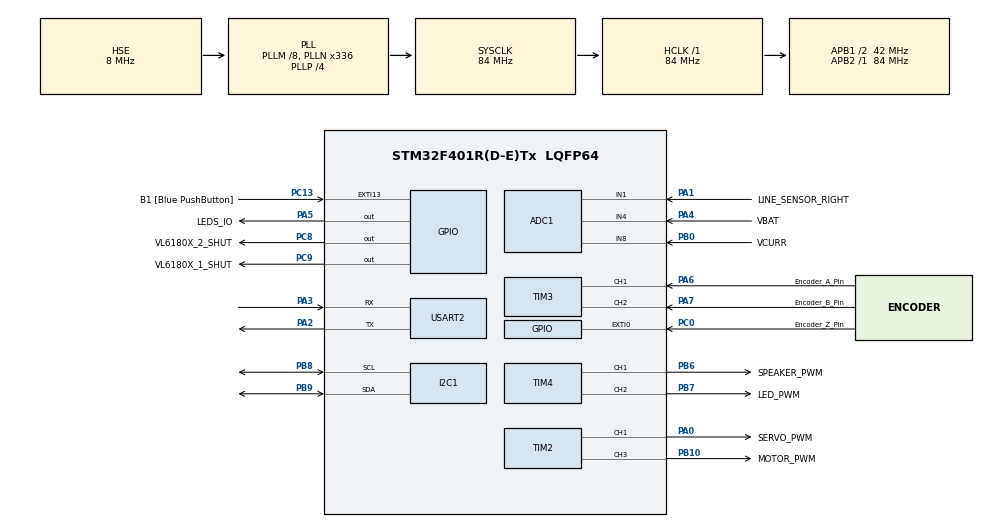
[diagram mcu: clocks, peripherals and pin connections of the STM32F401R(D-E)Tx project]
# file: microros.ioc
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ADC1.Channel-1\#ChannelRegularConversion=ADC_CHANNEL_1
ADC1.Channel-2\#ChannelRegularConversion=ADC_CHANNEL_4
ADC1.Channel-3\#ChannelRegularConversion=ADC_CHANNEL_8
ADC1.ContinuousConvMode=ENABLE
ADC1.DMAContinuousRequests=ENABLE
ADC1.EOCSelection=ADC_EOC_SEQ_CONV
ADC1.NbrOfConversion=3
ADC1.NbrOfConversionFlag=1
ADC1.Rank-1\#ChannelRegularConversion=1
ADC1.Rank-2\#ChannelRegularConversion=2
ADC1.Rank-3\#ChannelRegularConversion=3
ADC1.SamplingTime-1\#ChannelRegularConversion=ADC_SAMPLETIME_480CYCLES
ADC1.SamplingTime-2\#ChannelRegularConversion=ADC_SAMPLETIME_480CYCLES
ADC1.SamplingTime-3\#ChannelRegularConversion=ADC_SAMPLETIME_480CYCLES
ADC1.ScanConvMode=ENABLE
ADC1.master=1
Dma.ADC1.2.Direction=DMA_PERIPH_TO_MEMORY
Dma.ADC1.2.FIFOMode=DMA_FIFOMODE_DISABLE
Dma.ADC1.2.Instance=DMA2_Stream0
Dma.ADC1.2.MemDataAlignment=DMA_MDATAALIGN_WORD
Dma.ADC1.2.MemInc=DMA_MINC_ENABLE
Dma.ADC1.2.Mode=DMA_CIRCULAR
Dma.ADC1.2.PeriphDataAlignment=DMA_PDATAALIGN_WORD
Dma.ADC1.2.PeriphInc=DMA_PINC_DISABLE
Dma.ADC1.2.Priority=DMA_PRIORITY_MEDIUM
Dma.Request0=USART2_RX
Dma.Request1=USART2_TX
Dma.Request2=ADC1
Dma.USART2_RX.0.Direction=DMA_PERIPH_TO_MEMORY
Dma.USART2_RX.0.FIFOMode=DMA_FIFOMODE_DISABLE
Dma.USART2_RX.0.Instance=DMA1_Stream5
Dma.USART2_RX.0.MemDataAlignment=DMA_MDATAALIGN_BYTE
Dma.USART2_RX.0.MemInc=DMA_MINC_ENABLE
Dma.USART2_RX.0.Mode=DMA_CIRCULAR
Dma.USART2_RX.0.PeriphDataAlignment=DMA_PDATAALIGN_BYTE
Dma.USART2_RX.0.PeriphInc=DMA_PINC_DISABLE
Dma.USART2_RX.0.Priority=DMA_PRIORITY_VERY_HIGH
Dma.USART2_TX.1.Direction=DMA_MEMORY_TO_PERIPH
Dma.USART2_TX.1.FIFOMode=DMA_FIFOMODE_DISABLE
Dma.USART2_TX.1.Instance=DMA1_Stream6
Dma.USART2_TX.1.MemDataAlignment=DMA_MDATAALIGN_BYTE
Dma.USART2_TX.1.MemInc=DMA_MINC_ENABLE
Dma.USART2_TX.1.Mode=DMA_NORMAL
Dma.USART2_TX.1.PeriphDataAlignment=DMA_PDATAALIGN_BYTE
Dma.USART2_TX.1.PeriphInc=DMA_PINC_DISABLE
Dma.USART2_TX.1.Priority=DMA_PRIORITY_VERY_HIGH
FREERTOS.Tasks01=defaultTask,24,3000,StartDefaultTask,Default,NULL,Static,defaultTaskBuffer,defaultTaskControlBlock
Mcu.Family=STM32F4
Mcu.Name=STM32F401R(D-E)Tx
Mcu.Package=LQFP64
Mcu.UserConstants=PUB_COUNT_MAX,14999;SERVO_PWM_COUNT_MAX,39999;SERVO_PRESCALER,41;ENC_COUNT_MAX,999;MOT_PRESCALER,41;ENC_PRESCALER,83;RASPI_UART_BAUD,1000000;PUB_PRESCALER,83;MOT_PWM_COUNT_MAX,39999
NVIC.DMA1_Stream5_IRQn=true\:5\:0\:false\:false\:true\:true\:false\:true\:true
NVIC.DMA1_Stream6_IRQn=true\:5\:0\:false\:false\:true\:true\:false\:true\:true
NVIC.DMA2_Stream0_IRQn=true\:5\:0\:false\:false\:true\:true\:false\:true\:true
NVIC.EXTI0_IRQn=true\:5\:0\:false\:false\:true\:true\:true\:true\:true
NVIC.EXTI15_10_IRQn=true\:5\:0\:false\:false\:true\:true\:true\:true\:true
NVIC.PriorityGroup=NVIC_PRIORITYGROUP_4
NVIC.TIM1_TRG_COM_TIM11_IRQn=true\:5\:0\:false\:false\:true\:true\:true\:true\:true
NVIC.TIM1_UP_TIM10_IRQn=true\:15\:0\:false\:false\:true\:false\:false\:true\:true
NVIC.TimeBase=TIM1_UP_TIM10_IRQn
NVIC.TimeBaseIP=TIM1
NVIC.USART2_IRQn=true\:5\:0\:false\:false\:true\:true\:false\:true\:true
PA0-WKUP.GPIO_Label=SERVO_PWM
PA0-WKUP.Signal=S_TIM2_CH1_ETR
PA1.GPIO_Label=LINE_SENSOR_RIGHT
PA1.Signal=ADCx_IN1
PA13.GPIO_Label=TMS
PA13.Mode=Serial_Wire
PA13.Signal=SYS_JTMS-SWDIO
PA14.GPIO_Label=TCK
PA14.Mode=Serial_Wire
PA14.Signal=SYS_JTCK-SWCLK
PA2.Mode=Asynchronous
PA2.Signal=USART2_TX
PA3.Mode=Asynchronous
PA3.Signal=USART2_RX
PA4.GPIO_Label=VBAT
PA4.Signal=ADCx_IN4
PA5.GPIO_Label=LEDS_IO
PA5.Signal=GPIO_Output
PA6.GPIO_Label=Encoder_A_Pin
PA6.Signal=S_TIM3_CH1
PA7.GPIO_Label=Encoder_B_Pin
PA7.Signal=S_TIM3_CH2
PB0.GPIO_Label=VCURR
PB0.Signal=ADCx_IN8
PB10.GPIO_Label=MOTOR_PWM
PB10.Signal=S_TIM2_CH3
PB3.GPIO_Label=SWO
PB3.Signal=SYS_JTDO-SWO
PB6.GPIO_Label=SPEAKER_PWM
PB6.Signal=S_TIM4_CH1
PB7.GPIO_Label=LED_PWM
PB7.Signal=S_TIM4_CH2
PB8.Mode=I2C
PB8.Signal=I2C1_SCL
PB9.Mode=I2C
PB9.Signal=I2C1_SDA
PC0.GPIO_Label=Encoder_Z_Pin
PC0.GPIO_PuPd=GPIO_PULLDOWN
PC0.Signal=GPXTI0
PC13-ANTI_TAMP.GPIO_Label=B1 [Blue PushButton]
PC13-ANTI_TAMP.Signal=GPXTI13
PC14-OSC32_IN.Mode=LSE-External-Oscillator
PC14-OSC32_IN.Signal=RCC_OSC32_IN
PC15-OSC32_OUT.Mode=LSE-External-Oscillator
PC15-OSC32_OUT.Signal=RCC_OSC32_OUT
PC8.GPIO_Label=VL6180X_2_SHUT
PC8.Signal=GPIO_Output
PC9.GPIO_Label=VL6180X_1_SHUT
PC9.Signal=GPIO_Output
PH0\ -\ OSC_IN.Mode=HSE-External-Clock-Source
PH0\ -\ OSC_IN.Signal=RCC_OSC_IN
PH1\ -\ OSC_OUT.Mode=HSE-External-Clock-Source
PH1\ -\ OSC_OUT.Signal=RCC_OSC_OUT
ProjectManager.HeapSize=0x200
ProjectManager.StackSize=0x400
ProjectManager.TargetToolchain=Makefile
RCC.48MHZClocksFreq_Value=84000000
RCC.AHBFreq_Value=84000000
RCC.APB1CLKDivider=RCC_HCLK_DIV2
RCC.APB1Freq_Value=42000000
RCC.APB1TimFreq_Value=84000000
RCC.APB2Freq_Value=84000000
RCC.APB2TimFreq_Value=84000000
RCC.CortexFreq_Value=84000000
RCC.HCLKFreq_Value=84000000
RCC.HSE_VALUE=8000000
RCC.HSI_VALUE=16000000
RCC.PLLM=8
RCC.PLLN=336
RCC.PLLP=RCC_PLLP_DIV4
RCC.PLLSourceVirtual=RCC_PLLSOURCE_HSE
RCC.SYSCLKFreq_VALUE=84000000
RCC.SYSCLKSource=RCC_SYSCLKSOURCE_PLLCLK
RCC.VCOOutputFreq_Value=336000000
SH.ADCx_IN1.0=ADC1_IN1,IN1
SH.ADCx_IN4.0=ADC1_IN4,IN4
SH.ADCx_IN8.0=ADC1_IN8,IN8
SH.S_TIM2_CH1_ETR.0=TIM2_CH1,PWM Generation1 CH1
SH.S_TIM2_CH3.0=TIM2_CH3,PWM Generation3 CH3
SH.S_TIM3_CH1.0=TIM3_CH1,Encoder_Interface
SH.S_TIM3_CH2.0=TIM3_CH2,Encoder_Interface
SH.S_TIM4_CH1.0=TIM4_CH1,PWM Generation1 CH1
SH.S_TIM4_CH2.0=TIM4_CH2,PWM Generation2 CH2
STMicroelectronics.X-CUBE-ALGOBUILD.1.4.0.LibraryCcDSPOoLibraryJjDSPOoLibrary=true
TIM10.Period=PUB_COUNT_MAX
TIM10.Prescaler=PUB_PRESCALER
TIM11.Period=ENC_COUNT_MAX
TIM11.Prescaler=ENC_PRESCALER
TIM2.Channel-PWM\ Generation1\ CH1=TIM_CHANNEL_1
TIM2.Channel-PWM\ Generation3\ CH3=TIM_CHANNEL_3
TIM2.Period=SERVO_PWM_COUNT_MAX
TIM2.Prescaler=SERVO_PRESCALER
TIM3.EncoderMode=TIM_ENCODERMODE_TI12
TIM3.IC1Filter=5
TIM3.IC2Filter=5
TIM4.Channel-PWM\ Generation1\ CH1=TIM_CHANNEL_1
TIM4.Channel-PWM\ Generation2\ CH2=TIM_CHANNEL_2
USART2.VirtualMode=VM_ASYNC
VP_FREERTOS_VS_CMSIS_V2.Mode=CMSIS_V2
VP_STMicroelectronics.X-CUBE-ALGOBUILD_VS_DSPOoLibraryJjLibrary_1.4.0_1.4.0.Mode=DSPOoLibraryJjLibrary
VP_SYS_VS_tim1.Mode=TIM1
VP_TIM10_VS_ClockSourceINT.Mode=Enable_Timer
VP_TIM11_VS_ClockSourceINT.Mode=Enable_Timer
VP_TIM2_VS_ClockSourceINT.Mode=Internal
board=custom

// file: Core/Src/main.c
/* USER CODE BEGIN Header */
/**
  ******************************************************************************
  * @file           : main.c
  * @brief          : Main program body
  ******************************************************************************
  * @attention
  *
  * Copyright (c) 2026 STMicroelectronics.
  * All rights reserved.
  *
  * This software is licensed under terms that can be found in the LICENSE file
  * in the root directory of this software component.
  * If no LICENSE file comes with this software, it is provided AS-IS.
  *
  ******************************************************************************
  */
/* USER CODE END Header */
#include "main.h"
#include "cmsis_os.h"
#include "adc.h"
#include "dma.h"
#include "i2c.h"
#include "tim.h"
#include "usart.h"
#include "gpio.h"

/* USER CODE BEGIN Includes */
#include "main.h"
#include "cmsis_os.h"
#include "adc.h"
#include "dma.h"
#include "i2c.h"
#include "tim.h"
#include "usart.h"
#include "gpio.h"
#include "arm_math.h"
#include "string.h"
#include "vl6180.h"
#include "speaker.h"
#include "stm32f4xx_hal_pwr.h"
/* USER CODE END Includes */

void SystemClock_Config(void);
void MX_FREERTOS_Init(void);

int main(void)
{

  /* MCU Configuration--------------------------------------------------------*/

  /* Reset of all peripherals, Initializes the Flash interface and the Systick. */
  HAL_Init();

  /* Configure the system clock */
  SystemClock_Config();

  /* Initialize all configured peripherals */
  MX_GPIO_Init();
  MX_DMA_Init();
  MX_USART2_UART_Init();
  MX_ADC1_Init();
  MX_I2C1_Init();
  MX_TIM2_Init();
  MX_TIM3_Init();
  MX_TIM4_Init();
  MX_TIM10_Init();
  MX_TIM11_Init();
  /* USER CODE BEGIN 2 */

  /* USER CODE BEGIN 2 */
//  while (1)
//  {
//      HAL_UART_Transmit(&huart2, (uint8_t*)"MAIN HELLO\r\n", 12, 100);
//      HAL_Delay(1000);
//  }
  /* USER CODE END 2 */

  /* Init scheduler */
  osKernelInitialize();  /* Call init function for freertos objects (in cmsis_os2.c) */
  MX_FREERTOS_Init();

  /* Start scheduler */
  osKernelStart();

  /* We should never get here as control is now taken by the scheduler */

  /* Infinite loop */
  while (1)
  {

  }
}

void SystemClock_Config(void)
{
  RCC_OscInitTypeDef RCC_OscInitStruct = {0};
  RCC_ClkInitTypeDef RCC_ClkInitStruct = {0};

  /** Configure the main internal regulator output voltage
  */
  __HAL_RCC_PWR_CLK_ENABLE();
  __HAL_PWR_VOLTAGESCALING_CONFIG(PWR_REGULATOR_VOLTAGE_SCALE2);

  /** Initializes the RCC Oscillators according to the specified parameters
  * in the RCC_OscInitTypeDef structure.
  */
  RCC_OscInitStruct.OscillatorType = RCC_OSCILLATORTYPE_HSE;
  RCC_OscInitStruct.HSEState = RCC_HSE_BYPASS;
  RCC_OscInitStruct.PLL.PLLState = RCC_PLL_ON;
  RCC_OscInitStruct.PLL.PLLSource = RCC_PLLSOURCE_HSE;
  RCC_OscInitStruct.PLL.PLLM = 8;
  RCC_OscInitStruct.PLL.PLLN = 336;
  RCC_OscInitStruct.PLL.PLLP = RCC_PLLP_DIV4;
  RCC_OscInitStruct.PLL.PLLQ = 4;
  if (HAL_RCC_OscConfig(&RCC_OscInitStruct) != HAL_OK)
  {
    Error_Handler();
  }

  /** Initializes the CPU, AHB and APB buses clocks
  */
  RCC_ClkInitStruct.ClockType = RCC_CLOCKTYPE_HCLK|RCC_CLOCKTYPE_SYSCLK
                              |RCC_CLOCKTYPE_PCLK1|RCC_CLOCKTYPE_PCLK2;
  RCC_ClkInitStruct.SYSCLKSource = RCC_SYSCLKSOURCE_PLLCLK;
  RCC_ClkInitStruct.AHBCLKDivider = RCC_SYSCLK_DIV1;
  RCC_ClkInitStruct.APB1CLKDivider = RCC_HCLK_DIV2;
  RCC_ClkInitStruct.APB2CLKDivider = RCC_HCLK_DIV1;

  if (HAL_RCC_ClockConfig(&RCC_ClkInitStruct, FLASH_LATENCY_2) != HAL_OK)
  {
    Error_Handler();
  }
}

void HAL_TIM_PeriodElapsedCallback(TIM_HandleTypeDef *htim)
{
  /* USER CODE BEGIN Callback 0 */
//
  /* USER CODE END Callback 0 */
  if (htim->Instance == TIM1)
  {
    HAL_IncTick();
  }
  /* USER CODE BEGIN Callback 1 */
//
  /* USER CODE END Callback 1 */
}

void Error_Handler(void)
{
  __disable_irq();
  while (1)
  {
  }
}
